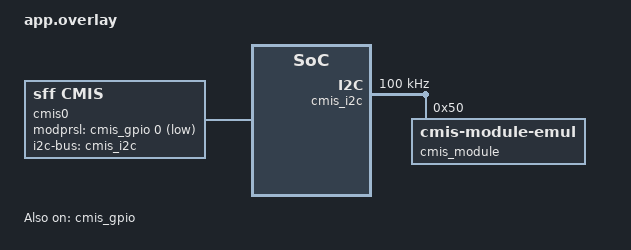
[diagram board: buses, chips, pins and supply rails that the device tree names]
/*
 * Copyright The Zephyr Project Contributors
 *
 * SPDX-License-Identifier: Apache-2.0
 */

#include <zephyr/dt-bindings/gpio/gpio.h>
#include <zephyr/dt-bindings/i2c/i2c.h>

/ {
	cmis0: qsfp-cage {
		compatible = "sff,cmis";
		i2c-bus = <&cmis_i2c>;
		modprsl-gpios = <&cmis_gpio 0 GPIO_ACTIVE_LOW>;
		status = "okay";
	};

	cmis_i2c: i2c@100 {
		compatible = "zephyr,i2c-emul-controller";
		reg = <0x100 4>;
		clock-frequency = <I2C_BITRATE_STANDARD>;
		#address-cells = <1>;
		#size-cells = <0>;
		status = "okay";

		/* the module plugged into the cage */
		cmis_module: cmis-module@50 {
			compatible = "zephyr,cmis-module-emul";
			reg = <0x50>;
			status = "okay";
		};
	};

	cmis_gpio: gpio@200 {
		compatible = "zephyr,gpio-emul";
		reg = <0x200 4>;
		gpio-controller;
		#gpio-cells = <2>;
		ngpios = <8>;
		status = "okay";
	};
};
